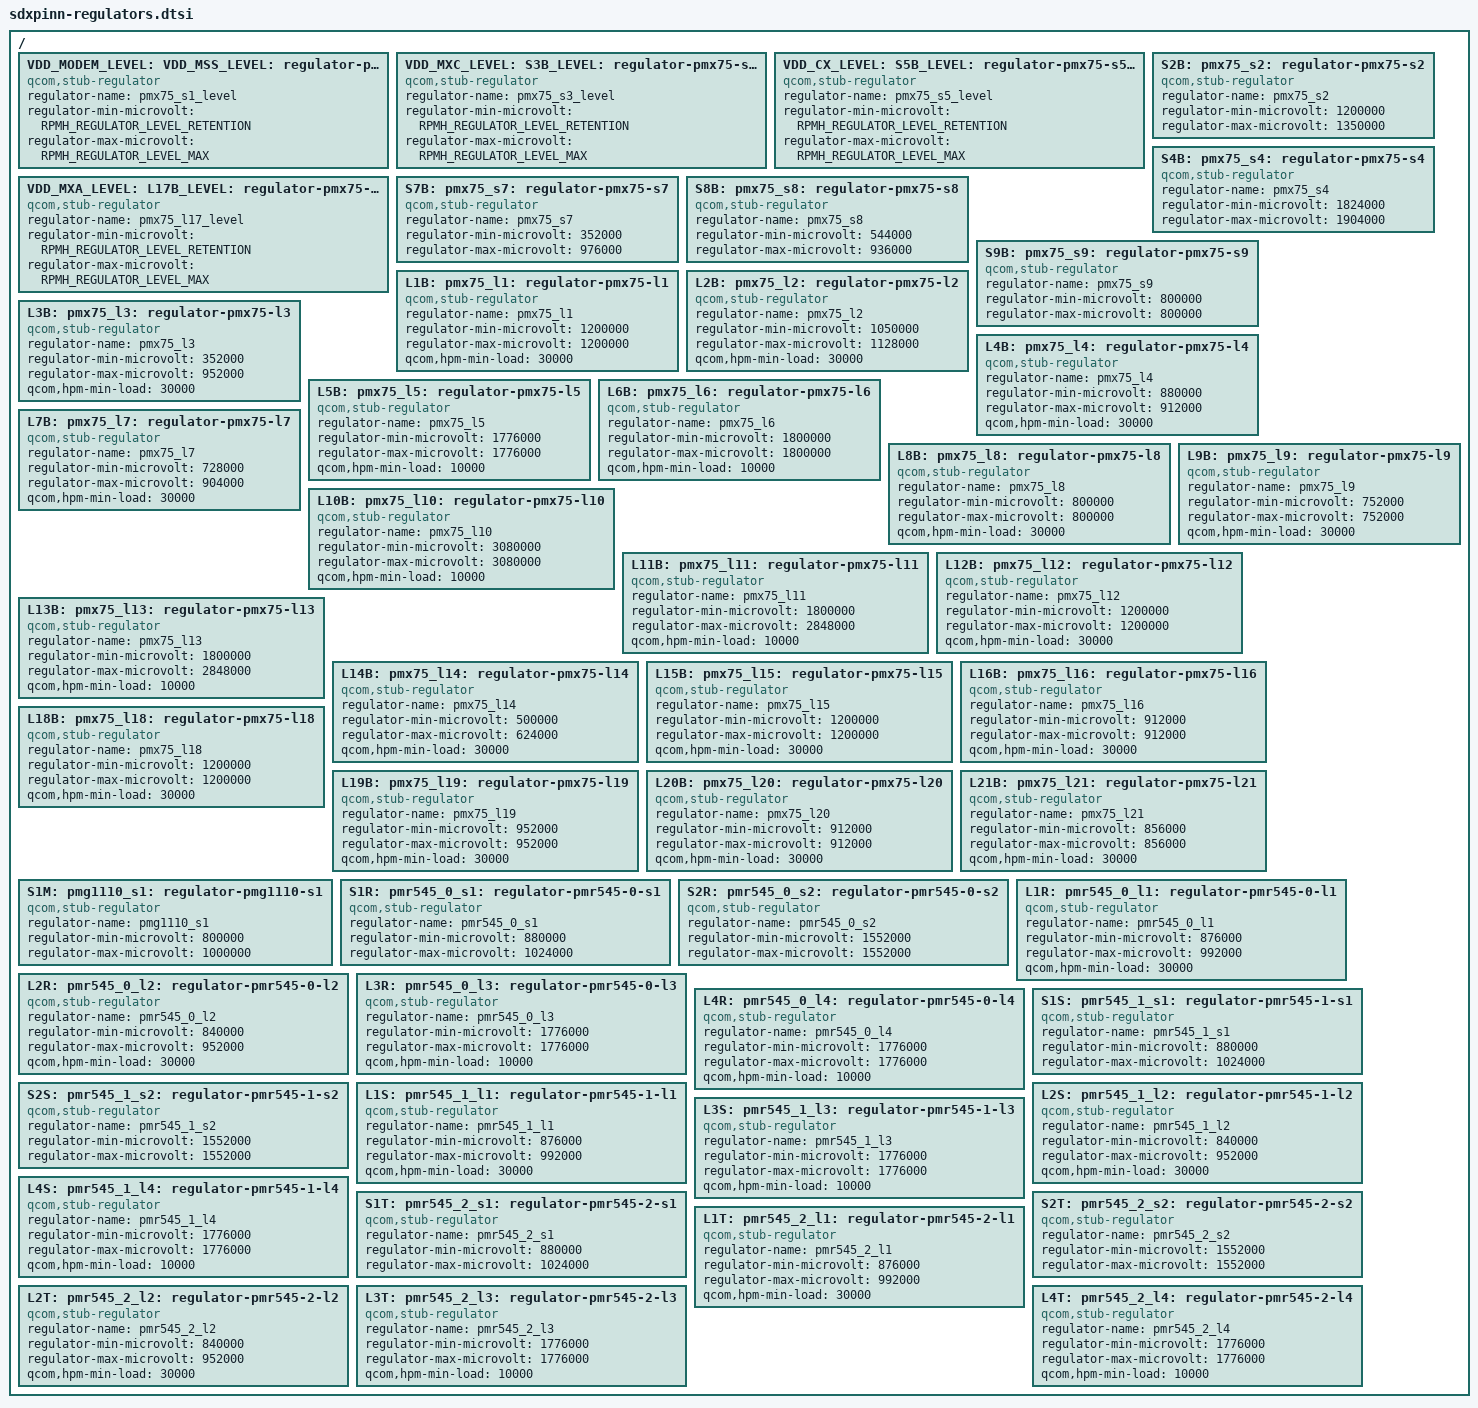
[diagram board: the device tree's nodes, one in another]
#include <dt-bindings/regulator/qcom,rpmh-regulator-levels.h>

/ {
	VDD_MODEM_LEVEL: VDD_MSS_LEVEL:
	S1B_LEVEL: pmx75_s1_level: regulator-pmx75-s1-level {
		compatible = "qcom,stub-regulator";
		regulator-name = "pmx75_s1_level";
		regulator-min-microvolt = <RPMH_REGULATOR_LEVEL_RETENTION>;
		regulator-max-microvolt = <RPMH_REGULATOR_LEVEL_MAX>;
	};

	VDD_MXC_LEVEL: S3B_LEVEL: pmx75_s3_level: regulator-pmx75-s3-level {
		compatible = "qcom,stub-regulator";
		regulator-name = "pmx75_s3_level";
		regulator-min-microvolt = <RPMH_REGULATOR_LEVEL_RETENTION>;
		regulator-max-microvolt = <RPMH_REGULATOR_LEVEL_MAX>;
	};

	VDD_CX_LEVEL: S5B_LEVEL: pmx75_s5_level: regulator-pmx75-s5-level {
		compatible = "qcom,stub-regulator";
		regulator-name = "pmx75_s5_level";
		regulator-min-microvolt = <RPMH_REGULATOR_LEVEL_RETENTION>;
		regulator-max-microvolt = <RPMH_REGULATOR_LEVEL_MAX>;
	};

	VDD_MXA_LEVEL: L17B_LEVEL: pmx75_l17_level: regulator-pmx75-l17-level {
		compatible = "qcom,stub-regulator";
		regulator-name = "pmx75_l17_level";
		regulator-min-microvolt = <RPMH_REGULATOR_LEVEL_RETENTION>;
		regulator-max-microvolt = <RPMH_REGULATOR_LEVEL_MAX>;
	};

	S2B: pmx75_s2: regulator-pmx75-s2 {
		compatible = "qcom,stub-regulator";
		regulator-name = "pmx75_s2";
		regulator-min-microvolt = <1200000>;
		regulator-max-microvolt = <1350000>;
	};

	S4B: pmx75_s4: regulator-pmx75-s4 {
		compatible = "qcom,stub-regulator";
		regulator-name = "pmx75_s4";
		regulator-min-microvolt = <1824000>;
		regulator-max-microvolt = <1904000>;
	};

	S7B: pmx75_s7: regulator-pmx75-s7 {
		compatible = "qcom,stub-regulator";
		regulator-name = "pmx75_s7";
		regulator-min-microvolt = <352000>;
		regulator-max-microvolt = <976000>;
	};

	S8B: pmx75_s8: regulator-pmx75-s8 {
		compatible = "qcom,stub-regulator";
		regulator-name = "pmx75_s8";
		regulator-min-microvolt = <544000>;
		regulator-max-microvolt = <936000>;
	};

	S9B: pmx75_s9: regulator-pmx75-s9 {
		compatible = "qcom,stub-regulator";
		regulator-name = "pmx75_s9";
		regulator-min-microvolt = <800000>;
		regulator-max-microvolt = <800000>;
	};

	L1B: pmx75_l1: regulator-pmx75-l1 {
		compatible = "qcom,stub-regulator";
		regulator-name = "pmx75_l1";
		regulator-min-microvolt = <1200000>;
		regulator-max-microvolt = <1200000>;
		qcom,hpm-min-load = <30000>;
	};

	L2B: pmx75_l2: regulator-pmx75-l2 {
		compatible = "qcom,stub-regulator";
		regulator-name = "pmx75_l2";
		regulator-min-microvolt = <1050000>;
		regulator-max-microvolt = <1128000>;
		qcom,hpm-min-load = <30000>;
	};

	L3B: pmx75_l3: regulator-pmx75-l3 {
		compatible = "qcom,stub-regulator";
		regulator-name = "pmx75_l3";
		regulator-min-microvolt = <352000>;
		regulator-max-microvolt = <952000>;
		qcom,hpm-min-load = <30000>;
	};

	L4B: pmx75_l4: regulator-pmx75-l4 {
		compatible = "qcom,stub-regulator";
		regulator-name = "pmx75_l4";
		regulator-min-microvolt = <880000>;
		regulator-max-microvolt = <912000>;
		qcom,hpm-min-load = <30000>;
	};

	L5B: pmx75_l5: regulator-pmx75-l5 {
		compatible = "qcom,stub-regulator";
		regulator-name = "pmx75_l5";
		regulator-min-microvolt = <1776000>;
		regulator-max-microvolt = <1776000>;
		qcom,hpm-min-load = <10000>;
	};

	L6B: pmx75_l6: regulator-pmx75-l6 {
		compatible = "qcom,stub-regulator";
		regulator-name = "pmx75_l6";
		regulator-min-microvolt = <1800000>;
		regulator-max-microvolt = <1800000>;
		qcom,hpm-min-load = <10000>;
	};

	L7B: pmx75_l7: regulator-pmx75-l7 {
		compatible = "qcom,stub-regulator";
		regulator-name = "pmx75_l7";
		regulator-min-microvolt = <728000>;
		regulator-max-microvolt = <904000>;
		qcom,hpm-min-load = <30000>;
	};

	L8B: pmx75_l8: regulator-pmx75-l8 {
		compatible = "qcom,stub-regulator";
		regulator-name = "pmx75_l8";
		regulator-min-microvolt = <800000>;
		regulator-max-microvolt = <800000>;
		qcom,hpm-min-load = <30000>;
	};

	L9B: pmx75_l9: regulator-pmx75-l9 {
		compatible = "qcom,stub-regulator";
		regulator-name = "pmx75_l9";
		regulator-min-microvolt = <752000>;
		regulator-max-microvolt = <752000>;
		qcom,hpm-min-load = <30000>;
	};

	L10B: pmx75_l10: regulator-pmx75-l10 {
		compatible = "qcom,stub-regulator";
		regulator-name = "pmx75_l10";
		regulator-min-microvolt = <3080000>;
		regulator-max-microvolt = <3080000>;
		qcom,hpm-min-load = <10000>;
	};

	L11B: pmx75_l11: regulator-pmx75-l11 {
		compatible = "qcom,stub-regulator";
		regulator-name = "pmx75_l11";
		regulator-min-microvolt = <1800000>;
		regulator-max-microvolt = <2848000>;
		qcom,hpm-min-load = <10000>;
	};

	L12B: pmx75_l12: regulator-pmx75-l12 {
		compatible = "qcom,stub-regulator";
		regulator-name = "pmx75_l12";
		regulator-min-microvolt = <1200000>;
		regulator-max-microvolt = <1200000>;
		qcom,hpm-min-load = <30000>;
	};

	L13B: pmx75_l13: regulator-pmx75-l13 {
		compatible = "qcom,stub-regulator";
		regulator-name = "pmx75_l13";
		regulator-min-microvolt = <1800000>;
		regulator-max-microvolt = <2848000>;
		qcom,hpm-min-load = <10000>;
	};

	L14B: pmx75_l14: regulator-pmx75-l14 {
		compatible = "qcom,stub-regulator";
		regulator-name = "pmx75_l14";
		regulator-min-microvolt = <500000>;
		regulator-max-microvolt = <624000>;
		qcom,hpm-min-load = <30000>;
	};

	L15B: pmx75_l15: regulator-pmx75-l15 {
		compatible = "qcom,stub-regulator";
		regulator-name = "pmx75_l15";
		regulator-min-microvolt = <1200000>;
		regulator-max-microvolt = <1200000>;
		qcom,hpm-min-load = <30000>;
	};

	L16B: pmx75_l16: regulator-pmx75-l16 {
		compatible = "qcom,stub-regulator";
		regulator-name = "pmx75_l16";
		regulator-min-microvolt = <912000>;
		regulator-max-microvolt = <912000>;
		qcom,hpm-min-load = <30000>;
	};

	L18B: pmx75_l18: regulator-pmx75-l18 {
		compatible = "qcom,stub-regulator";
		regulator-name = "pmx75_l18";
		regulator-min-microvolt = <1200000>;
		regulator-max-microvolt = <1200000>;
		qcom,hpm-min-load = <30000>;
	};

	L19B: pmx75_l19: regulator-pmx75-l19 {
		compatible = "qcom,stub-regulator";
		regulator-name = "pmx75_l19";
		regulator-min-microvolt = <952000>;
		regulator-max-microvolt = <952000>;
		qcom,hpm-min-load = <30000>;
	};

	L20B: pmx75_l20: regulator-pmx75-l20 {
		compatible = "qcom,stub-regulator";
		regulator-name = "pmx75_l20";
		regulator-min-microvolt = <912000>;
		regulator-max-microvolt = <912000>;
		qcom,hpm-min-load = <30000>;
	};

	L21B: pmx75_l21: regulator-pmx75-l21 {
		compatible = "qcom,stub-regulator";
		regulator-name = "pmx75_l21";
		regulator-min-microvolt = <856000>;
		regulator-max-microvolt = <856000>;
		qcom,hpm-min-load = <30000>;
	};

	S1M: pmg1110_s1: regulator-pmg1110-s1 {
		compatible = "qcom,stub-regulator";
		regulator-name = "pmg1110_s1";
		regulator-min-microvolt = <800000>;
		regulator-max-microvolt = <1000000>;
	};

	S1R: pmr545_0_s1: regulator-pmr545-0-s1 {
		compatible = "qcom,stub-regulator";
		regulator-name = "pmr545_0_s1";
		regulator-min-microvolt = <880000>;
		regulator-max-microvolt = <1024000>;
	};

	S2R: pmr545_0_s2: regulator-pmr545-0-s2 {
		compatible = "qcom,stub-regulator";
		regulator-name = "pmr545_0_s2";
		regulator-min-microvolt = <1552000>;
		regulator-max-microvolt = <1552000>;
	};

	L1R: pmr545_0_l1: regulator-pmr545-0-l1 {
		compatible = "qcom,stub-regulator";
		regulator-name = "pmr545_0_l1";
		regulator-min-microvolt = <876000>;
		regulator-max-microvolt = <992000>;
		qcom,hpm-min-load = <30000>;
	};

	L2R: pmr545_0_l2: regulator-pmr545-0-l2 {
		compatible = "qcom,stub-regulator";
		regulator-name = "pmr545_0_l2";
		regulator-min-microvolt = <840000>;
		regulator-max-microvolt = <952000>;
		qcom,hpm-min-load = <30000>;
	};

	L3R: pmr545_0_l3: regulator-pmr545-0-l3 {
		compatible = "qcom,stub-regulator";
		regulator-name = "pmr545_0_l3";
		regulator-min-microvolt = <1776000>;
		regulator-max-microvolt = <1776000>;
		qcom,hpm-min-load = <10000>;
	};

	L4R: pmr545_0_l4: regulator-pmr545-0-l4 {
		compatible = "qcom,stub-regulator";
		regulator-name = "pmr545_0_l4";
		regulator-min-microvolt = <1776000>;
		regulator-max-microvolt = <1776000>;
		qcom,hpm-min-load = <10000>;
	};

	S1S: pmr545_1_s1: regulator-pmr545-1-s1 {
		compatible = "qcom,stub-regulator";
		regulator-name = "pmr545_1_s1";
		regulator-min-microvolt = <880000>;
		regulator-max-microvolt = <1024000>;
	};

	S2S: pmr545_1_s2: regulator-pmr545-1-s2 {
		compatible = "qcom,stub-regulator";
		regulator-name = "pmr545_1_s2";
		regulator-min-microvolt = <1552000>;
		regulator-max-microvolt = <1552000>;
	};

	L1S: pmr545_1_l1: regulator-pmr545-1-l1 {
		compatible = "qcom,stub-regulator";
		regulator-name = "pmr545_1_l1";
		regulator-min-microvolt = <876000>;
		regulator-max-microvolt = <992000>;
		qcom,hpm-min-load = <30000>;
	};

	L2S: pmr545_1_l2: regulator-pmr545-1-l2 {
		compatible = "qcom,stub-regulator";
		regulator-name = "pmr545_1_l2";
		regulator-min-microvolt = <840000>;
		regulator-max-microvolt = <952000>;
		qcom,hpm-min-load = <30000>;
	};

	L3S: pmr545_1_l3: regulator-pmr545-1-l3 {
		compatible = "qcom,stub-regulator";
		regulator-name = "pmr545_1_l3";
		regulator-min-microvolt = <1776000>;
		regulator-max-microvolt = <1776000>;
		qcom,hpm-min-load = <10000>;
	};

	L4S: pmr545_1_l4: regulator-pmr545-1-l4 {
		compatible = "qcom,stub-regulator";
		regulator-name = "pmr545_1_l4";
		regulator-min-microvolt = <1776000>;
		regulator-max-microvolt = <1776000>;
		qcom,hpm-min-load = <10000>;
	};

	S1T: pmr545_2_s1: regulator-pmr545-2-s1 {
		compatible = "qcom,stub-regulator";
		regulator-name = "pmr545_2_s1";
		regulator-min-microvolt = <880000>;
		regulator-max-microvolt = <1024000>;
	};

	S2T: pmr545_2_s2: regulator-pmr545-2-s2 {
		compatible = "qcom,stub-regulator";
		regulator-name = "pmr545_2_s2";
		regulator-min-microvolt = <1552000>;
		regulator-max-microvolt = <1552000>;
	};

	L1T: pmr545_2_l1: regulator-pmr545-2-l1 {
		compatible = "qcom,stub-regulator";
		regulator-name = "pmr545_2_l1";
		regulator-min-microvolt = <876000>;
		regulator-max-microvolt = <992000>;
		qcom,hpm-min-load = <30000>;
	};

	L2T: pmr545_2_l2: regulator-pmr545-2-l2 {
		compatible = "qcom,stub-regulator";
		regulator-name = "pmr545_2_l2";
		regulator-min-microvolt = <840000>;
		regulator-max-microvolt = <952000>;
		qcom,hpm-min-load = <30000>;
	};

	L3T: pmr545_2_l3: regulator-pmr545-2-l3 {
		compatible = "qcom,stub-regulator";
		regulator-name = "pmr545_2_l3";
		regulator-min-microvolt = <1776000>;
		regulator-max-microvolt = <1776000>;
		qcom,hpm-min-load = <10000>;
	};

	L4T: pmr545_2_l4: regulator-pmr545-2-l4 {
		compatible = "qcom,stub-regulator";
		regulator-name = "pmr545_2_l4";
		regulator-min-microvolt = <1776000>;
		regulator-max-microvolt = <1776000>;
		qcom,hpm-min-load = <10000>;
	};
};
